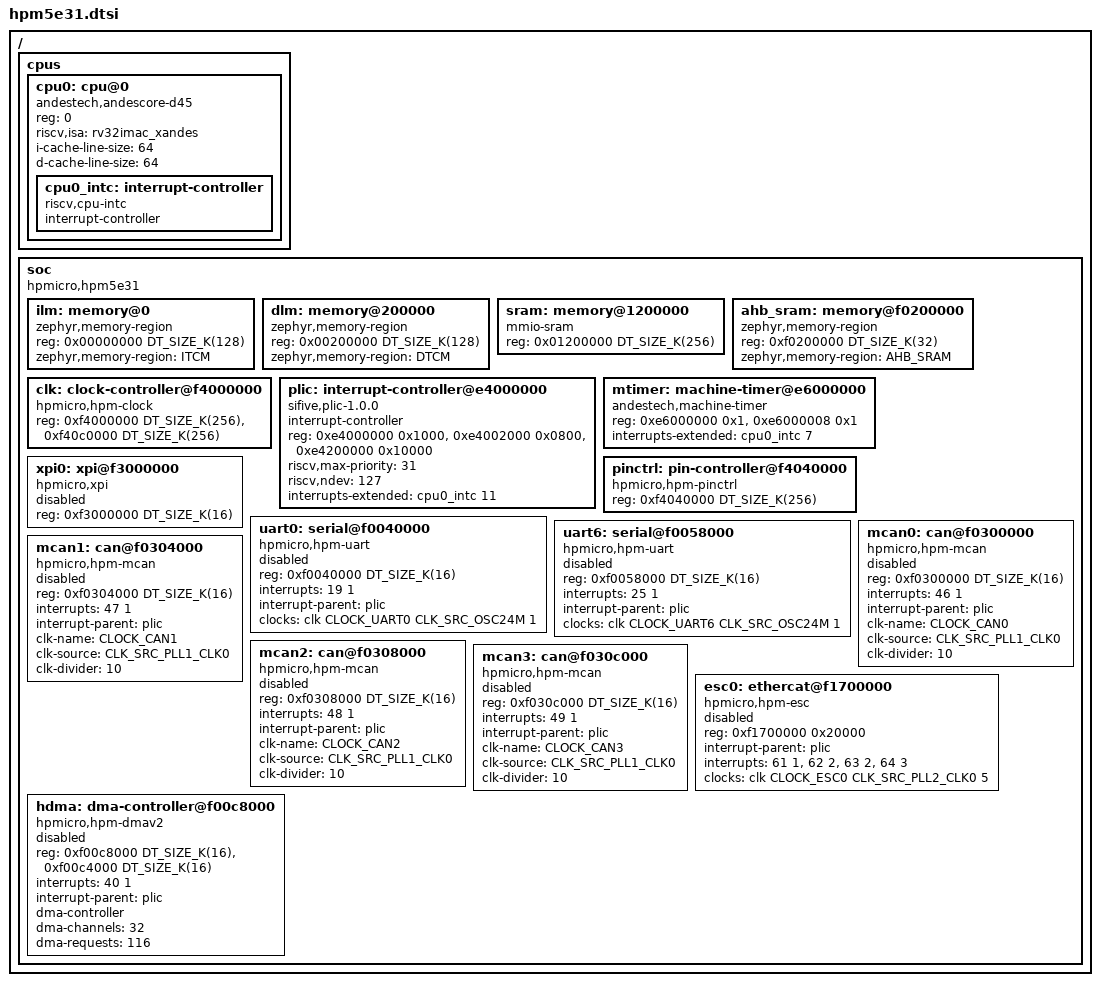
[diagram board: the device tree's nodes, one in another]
/* SPDX-License-Identifier: Apache-2.0 */

/dts-v1/;
#include <dt-bindings/clock/hpm5e31-clocks.h>
#include <mem.h>

/ {
	#address-cells = <1>;
	#size-cells = <1>;

	cpus {
		#address-cells = <1>;
		#size-cells = <0>;
		cpu0: cpu@0 {
			compatible = "andestech,andescore-d45", "riscv";
			reg = <0>;
			status = "okay";
			riscv,isa = "rv32imac_xandes";
			i-cache-line-size = <64>;
			d-cache-line-size = <64>;

			cpu0_intc: interrupt-controller {
				compatible = "riscv,cpu-intc";
				#address-cells = <0>;
				#interrupt-cells = <1>;
				interrupt-controller;
			};
		};
	};

	soc {
		#address-cells = <1>;
		#size-cells = <1>;
		compatible = "hpmicro,hpm5e31";
		ranges;

		ilm: memory@0 {
			compatible = "zephyr,memory-region";
			reg = <0x00000000 DT_SIZE_K(128)>;
			zephyr,memory-region = "ITCM";
		};

		dlm: memory@200000 {
			compatible = "zephyr,memory-region";
			reg = <0x00200000 DT_SIZE_K(128)>;
			zephyr,memory-region = "DTCM";
		};

		sram: memory@1200000 {
			compatible = "mmio-sram";
			reg = <0x01200000 DT_SIZE_K(256)>;
		};

		ahb_sram: memory@f0200000 {
			compatible = "zephyr,memory-region";
			reg = <0xf0200000 DT_SIZE_K(32)>;
			zephyr,memory-region = "AHB_SRAM";
		};

		clk: clock-controller@f4000000 {
			compatible = "hpmicro,hpm-clock";
			reg = <0xf4000000 DT_SIZE_K(256)>,
			      <0xf40c0000 DT_SIZE_K(256)>;
			reg-names = "sysctl", "pllv2";
			#clock-cells = <3>;
			status = "okay";
		};

		plic: interrupt-controller@e4000000 {
			compatible = "sifive,plic-1.0.0";
			#address-cells = <1>;
			#interrupt-cells = <2>;
			interrupt-controller;
			reg = <0xe4000000 0x1000>,
			      <0xe4002000 0x0800>,
			      <0xe4200000 0x10000>;
			reg-names = "prio", "irq_en", "reg";
			riscv,max-priority = <31>;
			riscv,ndev = <127>;
			interrupts-extended = <&cpu0_intc 11>;
		};

		mtimer: machine-timer@e6000000 {
			compatible = "andestech,machine-timer";
			reg = <0xe6000000 0x1>, <0xe6000008 0x1>;
			interrupts-extended = <&cpu0_intc 7>;
		};

		pinctrl: pin-controller@f4040000 {
			compatible = "hpmicro,hpm-pinctrl";
			reg = <0xf4040000 DT_SIZE_K(256)>;
			status = "okay";
		};

		xpi0: xpi@f3000000 {
			compatible = "hpmicro,xpi";
			reg = <0xf3000000 DT_SIZE_K(16)>;
			#address-cells = <1>;
			#size-cells = <1>;
			status = "disabled";
		};

		uart0: serial@f0040000 {
			compatible = "hpmicro,hpm-uart";
			reg = <0xf0040000 DT_SIZE_K(16)>;
			interrupts = <19 1>;
			interrupt-parent = <&plic>;
			clocks = <&clk CLOCK_UART0 CLK_SRC_OSC24M 1>;
			status = "disabled";
		};

		uart6: serial@f0058000 {
			compatible = "hpmicro,hpm-uart";
			reg = <0xf0058000 DT_SIZE_K(16)>;
			interrupts = <25 1>;
			interrupt-parent = <&plic>;
			clocks = <&clk CLOCK_UART6 CLK_SRC_OSC24M 1>;
			status = "disabled";
		};

		mcan0: can@f0300000 {
			compatible = "hpmicro,hpm-mcan";
			reg = <0xf0300000 DT_SIZE_K(16)>;
			interrupts = <46 1>;
			interrupt-parent = <&plic>;
			clk-name = <CLOCK_CAN0>;
			clk-source = <CLK_SRC_PLL1_CLK0>;
			clk-divider = <10>;
			status = "disabled";
		};

		mcan1: can@f0304000 {
			compatible = "hpmicro,hpm-mcan";
			reg = <0xf0304000 DT_SIZE_K(16)>;
			interrupts = <47 1>;
			interrupt-parent = <&plic>;
			clk-name = <CLOCK_CAN1>;
			clk-source = <CLK_SRC_PLL1_CLK0>;
			clk-divider = <10>;
			status = "disabled";
		};

		mcan2: can@f0308000 {
			compatible = "hpmicro,hpm-mcan";
			reg = <0xf0308000 DT_SIZE_K(16)>;
			interrupts = <48 1>;
			interrupt-parent = <&plic>;
			clk-name = <CLOCK_CAN2>;
			clk-source = <CLK_SRC_PLL1_CLK0>;
			clk-divider = <10>;
			status = "disabled";
		};

		mcan3: can@f030c000 {
			compatible = "hpmicro,hpm-mcan";
			reg = <0xf030c000 DT_SIZE_K(16)>;
			interrupts = <49 1>;
			interrupt-parent = <&plic>;
			clk-name = <CLOCK_CAN3>;
			clk-source = <CLK_SRC_PLL1_CLK0>;
			clk-divider = <10>;
			status = "disabled";
		};

		esc0: ethercat@f1700000 {
			compatible = "hpmicro,hpm-esc";
			reg = <0xf1700000 0x20000>;
			interrupt-parent = <&plic>;
			interrupts = <61 1>, <62 2>, <63 2>, <64 3>;
			interrupt-names = "pdi", "sync0", "sync1", "reset";
			clocks = <&clk CLOCK_ESC0 CLK_SRC_PLL2_CLK0 5>;
			status = "disabled";
		};

		hdma: dma-controller@f00c8000 {
			compatible = "hpmicro,hpm-dmav2";
			reg = <0xf00c8000 DT_SIZE_K(16)>,
			      <0xf00c4000 DT_SIZE_K(16)>;
			reg-names = "hdma", "dmamux";
			interrupts = <40 1>;
			interrupt-parent = <&plic>;
			dma-controller;
			#dma-cells = <2>;
			dma-channels = <32>;
			dma-requests = <116>;
			status = "disabled";
		};
	};
};
